# STM32MP13xx register map
File version: 1.7
CPU: CA7 r0p0, little endian, MPU, FPU, 4 interrupt priority bits
Registers are 32-bit, read-write, reset 0x0 unless marked. A register's access mark holds for its fields unless they carry their own. Offsets are from the block's base; [hi:lo] are bit positions; {n}, {i} and the like mark numbered series; 'fields as' and 'values as' point back to an identical list.

## SAES — SAES register block
Base 0x54005000
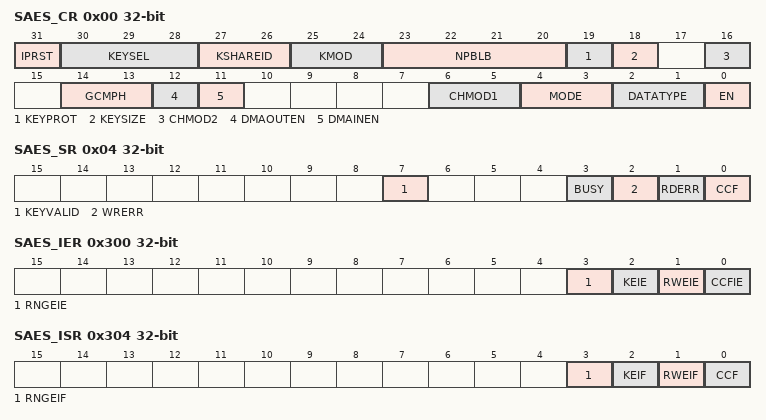
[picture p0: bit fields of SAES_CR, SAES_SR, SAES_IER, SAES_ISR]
0x00 SAES_CR — SAES control register
  [31] IPRST — SAES peripheral software reset Setting the bit resets the SAES peripheral, putting all registers to their default values, except the IPRST bit itself and the SAES_DPACFG register. Hence, any key-relative data is lost. For this reason, it is recommended to set the bit before handing over the SAES to a less secure application. The bit must be low while writing any configuration registers.
  [30:28] KEYSEL — Key selection The bitfield defines the source of the key information to use in the AES cryptographic core. Others: Reserved (if used, unfreeze SAES with IPRST) When KEYSEL is different from zero selected key value is available in key registers when BUSY bit is cleared and KEYVALID is set in SAES_SR register. Key error flag KEIF is set otherwise. Repeated writing of KEYSEL[2:0] with the same non-zero value only triggers the loading of DHUK or BHK if KEYVALID = 0. When application changes the key selection by writing to KEYSEL[2:0] bitfield, the key registers are immediately erased and the KEYVALID flag cleared. At the end of the decryption process, if KMOD[1:0] is other than zero, KEYSEL[2:0] is cleared. With the bitfield value other than zero and KEYVALID set, the application cannot transfer the ownership of SAES with a loaded key to an application running in another security context (such as secure, non-secure, specific CPU). More specifically, when security or Compartment ID of an access to any register does not match the information recorded by SAES, the KEIF flag is set. Attempts to write the bitfield are ignored when the BUSY flag of SAES_SR register is set, as well as when the EN bit of the SAES_CR register is set before the write access and it is not cleared by that write access.
    0=Software key, loaded in key registers SAES_KEYx; 1=Derived hardware unique key (DHUK); 2=Boot hardware key (BHK); 4=XOR of DHUK and BHK; 7=Test mode key (256-bit hardware constant 0xA5A5...A5A5)
  [27:26] KSHAREID — Key share identification This bitfield defines, at the end of a decryption process with KMOD[1:0]=10 (shared key), which target can read the SAES key registers using a dedicated hardware bus. Others: Reserved Attempts to write the bitfield are ignored when the BUSY flag of SAES_SR register is set, as well as when the EN bit of the SAES_CR register is set before the write access and it is not cleared by that write access.
    0=CRYP1 peripheral; 1=CRYP2 peripheral
  [25:24] KMOD — Key mode selection The bitfield defines how the SAES key can be used by the application: Others: Reserved With normal key selection, the key registers are freely usable, no specific usage or protection applies to SAES_DIN and SAES_DOUT registers. With wrapped key selection, the key loaded in key registers can only be used to encrypt or decrypt AES keys. Hence, when a decryption is selected in Wrapped-key mode read-as-zero SAES_DOUT register is automatically loaded into SAES key registers after a successful decryption process. With shared key selection, after a successful decryption process, SAES key registers are shared with the peripheral described in KSHAREID(1:0] bitfield. This sharing is valid only while KMOD[1:0]=10 and KEYVALID = 1. When a decryption is selected, read-as-zero SAES_DOUT register is automatically loaded into SAES key registers after a successful decryption process. With KMOD[1:0] other than zero, any attempt to configure the SAES peripheral for use by an application belonging to a different security domain (such as secure, non-secure, another CPU) results in automatic key erasure and setting of the KEIF flag. Attempts to write the bitfield are ignored when the BUSY flag of SAES_SR register is set, as well as when the EN bit of the SAES_CR register is set before the write access and it is not cleared by that write access.
    0=Normal key; 1=Wrapped key; 2=Shared key
  [23:20] NPBLB — Number of padding bytes in last block The bitfield sets the number of padding bytes in last block of payload: ...
    0=All bytes are valid (no padding); 1=Padding for one least-significant byte of last block; 15=Padding for 15 least-significant bytes of last block
  [19] KEYPROT — Key protection When set hardware-based key protection is enabled. Attempts to write the bit are ignored when the BUSY flag of SAES_SR register is set, as well as when the EN bit of the SAES_CR register is set before the write access and it is not cleared by that write access.
    0=When KEYVALID is set and KEYSEL=0 application can transfer the ownership of the SAES, with its loaded key, to an application running in another security context (such as non-secure, secure, specific CPU); 1=When KEYVALID is set, key error flag (KEIF) is set when an access to any registers is detected, this access having a security context (for example, secure, non-secure, Compartment ID) that does not match the one of the application that loaded the key
  [18] KEYSIZE — Key size selection This bitfield defines the length of the key used in the SAES cryptographic core, in bits: When KMOD[1:0]=01 or 10 KEYSIZE also defines the length of the key to encrypt or decrypt. Attempts to write the bit are ignored when the BUSY flag of SAES_SR register is set, as well as when the EN bit of the SAES_CR register is set before the write access and it is not cleared by that write access.
    0=128; 1=256
  [16] CHMOD2 — Chaining mode selection This bitfield selects the AES chaining mode: others: Reserved Attempts to write the bitfield are ignored when the BUSY flag of SAES_SR register is set, as well as when the EN bit of the SAES_CR register is set before the write access and it is not cleared by that write access.
  [14:13] GCMPH — GCM or CCM phase selection This bitfield selects the phase of GCM, GMAC or CCM algorithm: The bitfield has no effect if other than GCM, GMAC or CCM algorithms are selected (through the ALGOMODE bitfield).
    0=Init phase; 1=Header phase; 2=Payload phase; 3=Final phase
  [12] DMAOUTEN — DMA output enable This bit enables/disables data transferring with DMA, in the output phase: When the bit is set, DMA requests are automatically generated by SAES during the output data phase. This feature is only effective when Mode 1 or Mode 3 is selected through the MODE[1:0] bitfield. It is not effective for Mode 2 (key derivation).
    0=Disable; 1=Enable
  [11] DMAINEN — DMA input enable This bit enables/disables data transferring with DMA, in the input phase: When the bit is set, DMA requests are automatically generated by SAES during the input data phase. This feature is only effective when Mode 1 or Mode 3 is selected through the MODE[1:0] bitfield. It is not effective for Mode 2 (key derivation).
    0=Disable; 1=Enable
  [6:5] CHMOD1 — Chaining mode selection This bitfield selects the AES chaining mode: others: Reserved Attempts to write the bitfield are ignored when the BUSY flag of SAES_SR register is set, as well as when the EN bit of the SAES_CR register is set before the write access and it is not cleared by that write access.
  [4:3] MODE — SAES operating mode This bitfield selects the SAES operating mode: Attempts to write the bitfield are ignored when the BUSY flag of SAES_SR register is set, as well as when the EN bit of the SAES_CR register is set before the write access and it is not cleared by that write access.
    0=Mode 1: encryption; 1=Mode 2: key derivation (or key preparation for ECB/CBC decryption); 2=Mode 3: decryption
  [2:1] DATATYPE — Data type selection This bitfield defines the format of data written in the SAES_DINR register or read from the SAES_DOUTR register, through selecting the mode of data swapping: For more details, refer to . Attempts to write the bitfield are ignored when the BUSY flag of SAES_SR register is set, as well as when the EN bit of the SAES_CR register is set before the write access and it is not cleared by that write access.
    0=None; 1=Half-word (16-bit); 2=Byte (8-bit); 3=Bit
  [0] EN — SAES enable This bit enables/disables the SAES peripheral: At any moment, clearing then setting the bit re-initializes the SAES peripheral. This bit is automatically cleared by hardware upon the completion of the key preparation (Mode 2) and upon the completion of GCM/GMAC/CCM initial phase. The bit cannot be set as long as KEYVALID = 0 nor along with the following settings: KMOD = 01 + CHMOD = 011 and KMOD = 01 + CHMOD = 010 + MODE = 00. Note: With KMOD[1:0] other than 00, use the IPRST bit rather than the bit EN.
    0=Disable; 1=Enable
0x04 SAES_SR ro — SAES status register
  [7] KEYVALID — Key Valid flag This bit is set by hardware when the amount of key information defined by KEYSIZE in SAES_CR has been loaded in SAES_KEYx key registers. In normal mode when KEYSEL equals to zero, the application must write the key registers in the correct sequence, otherwise the KEIF flag of the SAES_ISR register is set and KEYVALID stays at zero. When KEYSEL is different from zero the BUSY flag is automatically set by SAES. When key is loaded successfully, the BUSY flag is cleared and KEYVALID set. Upon an error, the KEIF flag of the SAES_ISR register is set, the BUSY flag cleared and KEYVALID kept at zero. When the KEIF flag is set, the application must clear it through the SAES_ICR register, otherwise KEYVALID cannot be set. See the KEIF bit description for more details. For more information on key loading please refer to .
    0=No valid key information is available in key registers. EN bit in SAES_CR cannot be set.; 1=Valid key information, defined by KEYSIZE in SAES_CR, is loaded in key registers
  [3] BUSY — Busy This flag indicates whether SAES is idle or busy during GCM payload encryption phase: The flag is set upon SAES initialization, upon fetching random number from the RNG, or upon transferring a shared key to a target peripheral. When GCM encryption is selected, the flag must be at zero before selecting the GCM final phase.
    0=Idle; 1=Busy
  [2] WRERR — Write error This flag indicates the detection of an unexpected write operation to the SAES_DINR register (during computation or data output phase): The flag is set by hardware. It is cleared by software upon setting the RWEIF bit of the SAES_ICR register. Upon the flag setting, an interrupt is generated if enabled through the RWEIE bit of the SAES_ICR register. The flag setting has no impact on the SAES operation. Unexpected write is ignored.
    0=Not detected; 1=Detected
  [1] RDERR — Read error flag This flag indicates the detection of an unexpected read operation from the SAES_DOUTR register (during computation or data input phase): The flag is set by hardware. It is cleared by software upon setting the RWEIF bit of the SAES_ICR register. Upon the flag setting, an interrupt is generated if enabled through the RWEIE bit of the SAES_ICR register. The flag setting has no impact on the SAES operation. Unexpected read returns zero.
    0=Not detected; 1=Detected
  [0] CCF — Computation completed flag This bit mirrors the CCF bit of the SAES_ISR register.
0x08 SAES_DINR wo — SAES data input register
  [31:0] DIN — Input data word A four-fold sequential write to this bitfield during the input phase results in writing a complete 128-bit block of input data to the SAES peripheral. From the first to the fourth write, the corresponding data weights are [127:96], [95:64], [63:32], and [31:0]. Upon each write, the data from the 32-bit input buffer are handled by the data swap block according to the DATATYPE[1:0] bitfield, then written into the AES core 128-bit input buffer. The data signification of the input data block depends on the SAES operating mode: - Mode 1 (encryption): plaintext - Mode 2 (key derivation): the bitfield is not used (SAES_KEYRx registers used for input if KEYSEL=0) - Mode 3 (decryption): ciphertext The data swap operation is described in on page 1718.
0x0C SAES_DOUTR ro — SAES data output register
  [31:0] DOUT — Output data word This read-only bitfield fetches a 32-bit output buffer. A four-fold sequential read of this bitfield, upon the computation completion (CCF set), virtually reads a complete 128-bit block of output data from the SAES peripheral. Before reaching the output buffer, the data produced by the AES core are handled by the data swap block according to the DATATYPE[1:0] bitfield. Data weights from the first to the fourth read operation are: [127:96], [95:64], [63:32], and [31:0]. The data signification of the output data block depends on the SAES operating mode: - Mode 1 (encryption): ciphertext - Mode 2 (key derivation): the bitfield is not used - Mode 3 (decryption): plaintext The data swap operation is described in on page 1718.
0x10 SAES_KEYR0 wo — SAES key register 0
  [31:0] KEY — Cryptographic key, bits [31:0] This write-only bitfield contains the bits [31:0] of the AES encryption or decryption key, depending on the operating mode: - In Mode 1 (encryption), Mode 2 (key derivation): the value to write into the bitfield is the encryption key. - In Mode 3 (decryption): the value to write into the bitfield is the encryption key to be derived before being used for decryption. The SAES_KEYRx registers may be written only when KEYSIZE value is correct and when the SAES peripheral is disabled (EN bit of the SAES_CR register cleared). A special writing sequence is also required, as described in KEYVALID bit of the SAES_SR register. Note that, if KEYSEL is different from 0 and KEYVALID = 0, the key is directly loaded to SAES_KEYRx registers (hence writes to key register is ignored and KEIF is set). Refer to for more details.
{0x10+4i} SAES_KEYR{i} wo (i=1..3) — SAES key register {i}
  [31:0] KEY — Cryptographic key, bits [{32i+31}:{32i}] Refer to the SAES_KEYR0 register for description of the KEY[255:0] bitfield.
0x20 SAES_IVR0 — SAES initialization vector register 0
  [31:0] IVI — Initialization vector input, bits [31:0] Refer to for description of the IVI[127:0] bitfield. The initialization vector is only used in chaining modes other than ECB. The SAES_IVRx registers may be written only when the SAES peripheral is disabled
{0x20+4i} SAES_IVR{i} (i=1..3) — SAES initialization vector register {i}
  [31:0] IVI — Initialization vector input, bits [{32i+31}:{32i}] Refer to the SAES_IVR0 register for description of the IVI[128:0] bitfield.
{0x20+4i} SAES_KEYR{i} wo (i=4..7) — SAES key register {i}
  fields as SAES_KEYR1
{0x40+4i} SAES_SUSP{i}R (i=0..7) — SAES suspend registers
  [31:0] SUSP — SAES suspend Upon suspend operation, this bitfield of the corresponding SAES_SUSPxR register takes the value of one of internal SAES registers.
0x300 SAES_IER — SAES interrupt enable register
  [all] fields
    0=Disabled (masked); 1=Enabled (not masked)
  [3] RNGEIE — RNG error interrupt enable This bit enables or disables (masks) the SAES interrupt generation when RNGEIF (RNG error flag) is set.
  [2] KEIE — Key error interrupt enable This bit enables or disables (masks) the SAES interrupt generation when KEIF (key error flag) is set.
  [1] RWEIE — Read or write error interrupt enable This bit enables or disables (masks) the SAES interrupt generation when RWEIF (read and/or write error flag) is set.
  [0] CCFIE — Computation complete flag interrupt enable This bit enables or disables (masks) the SAES interrupt generation when CCF (computation complete flag) is set.
0x304 SAES_ISR ro — SAES interrupt status register
  [3] RNGEIF — RNG error interrupt flag This read-only bit is set by hardware when an error is detected on RNG bus interface (e.g. bad entropy). RNGEIE bit is cleared when application sets the corresponding bit of SAES_ICR register. An interrupt is generated if the RNGEIE bit has been previously set in the SAES_IER register. Clearing this bit triggers the reload of a new random number from RNG peripheral.
    0=RNG bus is functional; 1=Error detected on RNG bus interface (random seed fetching error)
  [2] KEIF — Key error interrupt flag This read-only bit is set by hardware when key information failed to load into key registers or key register usage is forbidden. KEIF bit is cleared when application sets the corresponding bit in SAES_ICR register. An interrupt is generated if the KEIE bit has been previously set in the SAES_IER register. KEIF is triggered if one of below error occurred: Application did not write SAES_KEYRx registers in the correct sequence. Specifically, If KEYSIZE=0 SAES_KEYR0, then SAES_KEYR1, then SAES_KEYR2 then SAES_KEYR3 register must be written (or the reverse order). If KEYSIZE=1 SAES_KEYR0, then SAES_KEYR1, then SAES_KEYR2 then SAES_KEYR3, then SAES_KEYR4, then SAES_KEYR5, then SAES_KEYR6, then SAES_KEYR7 register must be written (or the reverse order). SAES failed to load the DHUK (KEYSEL=001 or 100) SAES failed to load the BHK (KEYSEL=010 or 100) using the same sequence as above. AES failed to load the key shared by SAES peripheral (KMOD=10) When KEYVALID=1 and (KEYPROT=1 or KEYSEL not 0x0), security context of the application that loaded the key (secure, non-secure, CPU) does not match the security or Compartment ID attribute of the access to SAES_CR or SAES_DOUT. In this case KEYVALID and EN bits are cleared. KEIF must be cleared by application otherwise KEYVALID cannot be set.
    0=No key error detected; 1=Key information failed to load into key registers, or key register usage is forbidden
  [1] RWEIF — Read or write error interrupt flag This read-only bit is set by hardware when a RDERR or a WRERR error flag is set in the SAES_SR register. RWEIF bit is cleared when application sets the corresponding bit of SAES_ICR register. An interrupt is generated if the RWEIE bit has been previously set in the SAES_IER register. This flags has no meaning when key derivation mode is selected.
    0=No read or write error detected; 1=Read or write error detected (see SAES_SR register for details)
  [0] CCF — Computation complete flag This flag indicates whether the computation is completed: The flag is set by hardware upon the completion of the computation. It is cleared by software, upon setting the CCF bit of the SAES_ICR register. Upon the flag setting, an interrupt is generated if enabled through the CCFIE bit of the SAES_IER register. The flag is significant only when the DMAOUTEN bit is 0. It may stay high when DMA_EN is 1.
    0=Not completed; 1=Completed
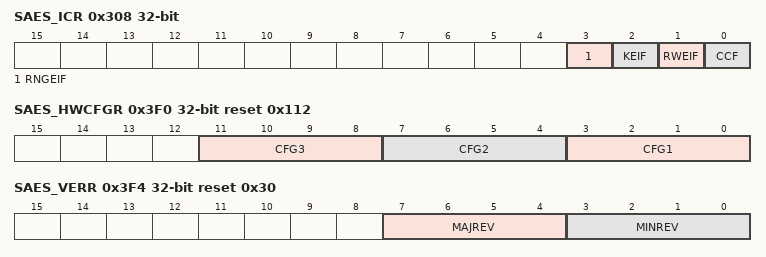
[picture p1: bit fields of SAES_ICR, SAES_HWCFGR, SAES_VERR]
0x308 SAES_ICR wo — SAES interrupt clear register
  [3] RNGEIF — RNG error interrupt flag clear Application must set this bit to clear the RNGEIF status bit in SAES_ISR register.
  [2] KEIF — Key error interrupt flag clear Application must set this bit to clear the KEIF status bit in SAES_ISR register.
  [1] RWEIF — Read or write error interrupt flag clear Application must set this bit to clear the RWEIF status bit in SAES_ISR register, and both RDERR and WRERR flags in SAES_SR register.
  [0] CCF — Computation complete flag clear Application must set this bit to clear the CCF status bit in SAES_SR and SAES_ISR register.
0x3F0 SAES_HWCFGR ro reset 0x112 — SAES hardware configuration register
  [11:8] CFG3 — HW Generic 3
  [7:4] CFG2 — HW Generic 2
  [3:0] CFG1 — HW Generic 1
0x3F4 SAES_VERR ro reset 0x30 — SAES version register
  [7:4] MAJREV — Major revision This bitfield returns the SAES peripheral major version (0x3).
  [3:0] MINREV — Minor revision This bitfield returns the SAES peripheral minor version (0x0).
0x3F8 SAES_IPIDR ro reset 0x170023 — SAES identification register
  [31:0] ID — Identification code of the peripheral This bitfield returns the identification code of the SAES peripheral.
0x3FC SAES_SIDR ro reset 0xA3C5DD01 — SAES size ID register
  [31:0] SID — Size identification code This bitfield returns the size identification code of the SAES peripheral as defined below: Bits[31:8] = 0xA3C5DD (fixed code) Bits[7:0] = 0x01 (1 Kbyte address decoding)
